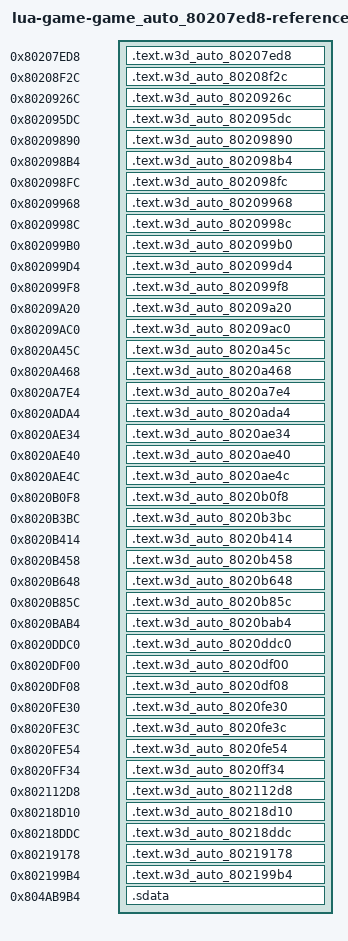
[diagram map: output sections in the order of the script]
/* Generated reference-only placements. All bodies are source-built. */
OUTPUT_FORMAT("elf32-powerpc")
OUTPUT_ARCH(powerpc)
ENTRY(w3d_auto_80207ed8)
_SDA_BASE_ = 0x804b2540;
_SDA2_BASE_ = 0x804c2540;
fn_801FC8AC = 0x801fc8ac;
fn_801FE1D8 = 0x801fe1d8;
fn_801FE45C = 0x801fe45c;
fn_80200B54 = 0x80200b54;
fn_80200BFC = 0x80200bfc;
fn_802069A4 = 0x802069a4;
fn_802069E0 = 0x802069e0;
fn_80207B30 = 0x80207b30;
fn_8020926C = 0x8020926c;
fn_802092B8 = 0x802092b8;
fn_802092C8 = 0x802092c8;
fn_802095D8 = 0x802095d8;
fn_802095DC = 0x802095dc;
fn_802095EC = 0x802095ec;
fn_80209638 = 0x80209638;
fn_80209720 = 0x80209720;
fn_802097AC = 0x802097ac;
fn_802098B4 = 0x802098b4;
fn_80209A70 = 0x80209a70;
fn_80209B2C = 0x80209b2c;
fn_8020B208 = 0x8020b208;
fn_8020C5C8 = 0x8020c5c8;
fn_8020DC54 = 0x8020dc54;
fn_8020FF44 = 0x8020ff44;
fn_80210010 = 0x80210010;
fn_802110CC = 0x802110cc;
fn_8021202C = 0x8021202c;
fn_80212BCC = 0x80212bcc;
fn_802178B8 = 0x802178b8;
fn_802E4CEC = 0x802e4cec;
fn_802F5320 = 0x802f5320;
SECTIONS {
  .text.w3d_auto_80207ed8 0x80207ed8 : { *(.text.w3d_auto_80207ed8) }
  .text.w3d_auto_80208f2c 0x80208f2c : { *(.text.w3d_auto_80208f2c) }
  .text.w3d_auto_8020926c 0x8020926c : { *(.text.w3d_auto_8020926c) }
  .text.w3d_auto_802095dc 0x802095dc : { *(.text.w3d_auto_802095dc) }
  .text.w3d_auto_80209890 0x80209890 : { *(.text.w3d_auto_80209890) }
  .text.w3d_auto_802098b4 0x802098b4 : { *(.text.w3d_auto_802098b4) }
  .text.w3d_auto_802098fc 0x802098fc : { *(.text.w3d_auto_802098fc) }
  .text.w3d_auto_80209968 0x80209968 : { *(.text.w3d_auto_80209968) }
  .text.w3d_auto_8020998c 0x8020998c : { *(.text.w3d_auto_8020998c) }
  .text.w3d_auto_802099b0 0x802099b0 : { *(.text.w3d_auto_802099b0) }
  .text.w3d_auto_802099d4 0x802099d4 : { *(.text.w3d_auto_802099d4) }
  .text.w3d_auto_802099f8 0x802099f8 : { *(.text.w3d_auto_802099f8) }
  .text.w3d_auto_80209a20 0x80209a20 : { *(.text.w3d_auto_80209a20) }
  .text.w3d_auto_80209ac0 0x80209ac0 : { *(.text.w3d_auto_80209ac0) }
  .text.w3d_auto_8020a45c 0x8020a45c : { *(.text.w3d_auto_8020a45c) }
  .text.w3d_auto_8020a468 0x8020a468 : { *(.text.w3d_auto_8020a468) }
  .text.w3d_auto_8020a7e4 0x8020a7e4 : { *(.text.w3d_auto_8020a7e4) }
  .text.w3d_auto_8020ada4 0x8020ada4 : { *(.text.w3d_auto_8020ada4) }
  .text.w3d_auto_8020ae34 0x8020ae34 : { *(.text.w3d_auto_8020ae34) }
  .text.w3d_auto_8020ae40 0x8020ae40 : { *(.text.w3d_auto_8020ae40) }
  .text.w3d_auto_8020ae4c 0x8020ae4c : { *(.text.w3d_auto_8020ae4c) }
  .text.w3d_auto_8020b0f8 0x8020b0f8 : { *(.text.w3d_auto_8020b0f8) }
  .text.w3d_auto_8020b3bc 0x8020b3bc : { *(.text.w3d_auto_8020b3bc) }
  .text.w3d_auto_8020b414 0x8020b414 : { *(.text.w3d_auto_8020b414) }
  .text.w3d_auto_8020b458 0x8020b458 : { *(.text.w3d_auto_8020b458) }
  .text.w3d_auto_8020b648 0x8020b648 : { *(.text.w3d_auto_8020b648) }
  .text.w3d_auto_8020b85c 0x8020b85c : { *(.text.w3d_auto_8020b85c) }
  .text.w3d_auto_8020bab4 0x8020bab4 : { *(.text.w3d_auto_8020bab4) }
  .text.w3d_auto_8020ddc0 0x8020ddc0 : { *(.text.w3d_auto_8020ddc0) }
  .text.w3d_auto_8020df00 0x8020df00 : { *(.text.w3d_auto_8020df00) }
  .text.w3d_auto_8020df08 0x8020df08 : { *(.text.w3d_auto_8020df08) }
  .text.w3d_auto_8020fe30 0x8020fe30 : { *(.text.w3d_auto_8020fe30) }
  .text.w3d_auto_8020fe3c 0x8020fe3c : { *(.text.w3d_auto_8020fe3c) }
  .text.w3d_auto_8020fe54 0x8020fe54 : { *(.text.w3d_auto_8020fe54) }
  .text.w3d_auto_8020ff34 0x8020ff34 : { *(.text.w3d_auto_8020ff34) }
  .text.w3d_auto_802112d8 0x802112d8 : { *(.text.w3d_auto_802112d8) }
  .text.w3d_auto_80218d10 0x80218d10 : { *(.text.w3d_auto_80218d10) }
  .text.w3d_auto_80218ddc 0x80218ddc : { *(.text.w3d_auto_80218ddc) }
  .text.w3d_auto_80219178 0x80219178 : { *(.text.w3d_auto_80219178) }
  .text.w3d_auto_802199b4 0x802199b4 : { *(.text.w3d_auto_802199b4) }
  .sdata 0x804ab9b4 (NOLOAD) : {
    . = 0x0; lbl_804AB9B4 = .;
    . = 0x4; lbl_804AB9B8 = .;
    . = 0x4c; lbl_804ABA00 = .;
    . = 0x50; lbl_804ABA04 = .;
    . = 0x54; lbl_804ABA08 = .;
    . = 0x80; lbl_804ABA34 = .;
    . = 0x4ca6; lbl_804B065A = .;
    . = 0x4ce8; lbl_804B069C = .;
    . = 0x4cf0; lbl_804B06A4 = .;
    . = 0x5f40; lbl_804B18F4 = .;
    . = 0x5f48; lbl_804B18FC = .;
    . = 0x5f4c; lbl_804B1900 = .;
    . = 0x5f54; lbl_804B1908 = .;
    . += 1; }
  /DISCARD/ : { *(.text*) *(.rodata*) *(.data*) *(.bss*) *(.sdata*) *(.sbss*) *(.comment) }
}
